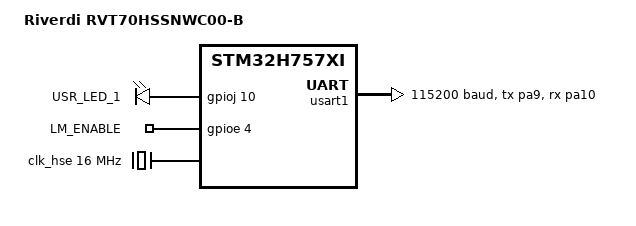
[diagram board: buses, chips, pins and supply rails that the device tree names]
/* SPDX-License-Identifier: Apache-2.0 */

/dts-v1/;
#include <st/h7/stm32h757Xi_m7.dtsi>
#include <st/h7/stm32h757xihx-pinctrl.dtsi>
#include <zephyr/dt-bindings/gpio/gpio.h>

/ {
	model = "Riverdi RVT70HSSNWC00-B";
	compatible = "riverdi,rvt70hssnwc00-b";

	chosen {
		zephyr,console = &usart1;
		zephyr,sram = &sram0;
		zephyr,flash = &flash0;
	};

	aliases {
		led0 = &user_led;
	};

	leds {
		compatible = "gpio-leds";

		user_led: led-0 {
			gpios = <&gpioj 10 GPIO_ACTIVE_HIGH>;
			label = "USR_LED_1";
		};

		/* Not actually an LED, but used as a node from which to fetch gpio_dt_spec in application */
		lm_enable: led-1 {
			gpios = <&gpioe 4 (GPIO_OPEN_DRAIN | GPIO_PULL_UP)>;
			label = "LM_ENABLE";
		};
	};
};

&pwr {
	power-supply = "ldo";
};

&clk_hse {
	clock-frequency = <DT_FREQ_M(16)>;
	hse-bypass;
	status = "okay";
};

&pll {
	div-m = <4>;
	mul-n = <240>;
	div-p = <2>;
	div-q = <24>;
	div-r = <12>;
	clocks = <&clk_hse>;
	status = "okay";
};

&rcc {
	clocks = <&pll>;
	clock-frequency = <DT_FREQ_M(480)>;
	d1cpre = <1>;
	hpre = <2>;
	d1ppre = <2>;
	d2ppre1 = <2>;
	d2ppre2 = <2>;
	d3ppre = <2>;
};

&usart1 {
	pinctrl-0 = <&usart1_tx_pa9 &usart1_rx_pa10>;
	pinctrl-names = "default";
	current-speed = <115200>;
	status = "okay";
};
